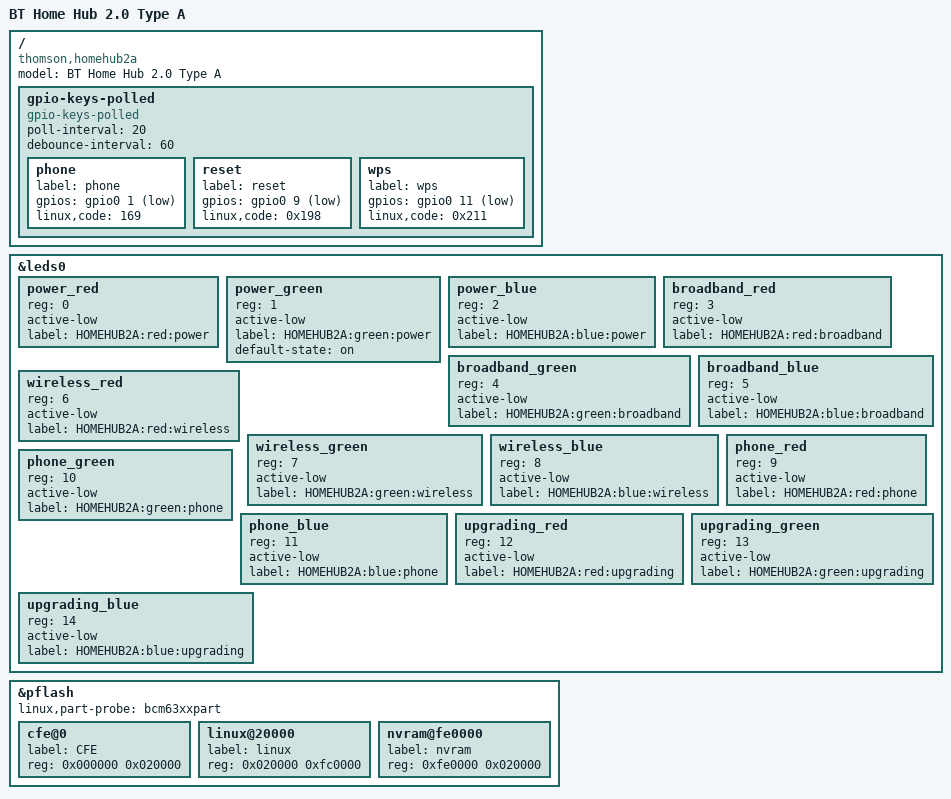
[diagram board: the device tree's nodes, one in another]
/dts-v1/;

/include/ "bcm6358.dtsi"

/ {
	model = "BT Home Hub 2.0 Type A";
	compatible = "thomson,homehub2a", "brcm,bcm6358";

	gpio-keys-polled {
		compatible = "gpio-keys-polled";
		#address-cells = <1>;
		#size-cells = <0>;
		poll-interval = <20>;
		debounce-interval = <60>;

		phone {
			label = "phone";
			gpios = <&gpio0 1 1>;
			linux,code = <169>;
		};
		reset {
			label = "reset";
			gpios = <&gpio0 9 1>;
			linux,code = <0x198>;
		};
		wps {
			label = "wps";
			gpios = <&gpio0 11 1>;
			linux,code = <0x211>;
		};
	};
};

&leds0 {
	status = "ok";

	power_red {
		reg = <0>;
		active-low;
		label = "HOMEHUB2A:red:power";
	};
	power_green {
		reg = <1>;
		active-low;
		label = "HOMEHUB2A:green:power";
		default-state = "on";
	};
	power_blue {
		reg = <2>;
		active-low;
		label = "HOMEHUB2A:blue:power";
	};
	broadband_red {
		reg = <3>;
		active-low;
		label = "HOMEHUB2A:red:broadband";
	};
	broadband_green {
		reg = <4>;
		active-low;
		label = "HOMEHUB2A:green:broadband";
	};
	broadband_blue {
		reg = <5>;
		active-low;
		label = "HOMEHUB2A:blue:broadband";
	};
	wireless_red {
		reg = <6>;
		active-low;
		label = "HOMEHUB2A:red:wireless";
	};
	wireless_green {
		reg = <7>;
		active-low;
		label = "HOMEHUB2A:green:wireless";
	};
	wireless_blue {
		reg = <8>;
		active-low;
		label = "HOMEHUB2A:blue:wireless";
	};
	phone_red {
		reg = <9>;
		active-low;
		label = "HOMEHUB2A:red:phone";
	};
	phone_green {
		reg = <10>;
		active-low;
		label = "HOMEHUB2A:green:phone";
	};
	phone_blue {
		reg = <11>;
		active-low;
		label = "HOMEHUB2A:blue:phone";
	};
	upgrading_red {
		reg = <12>;
		active-low;
		label = "HOMEHUB2A:red:upgrading";
	};
	upgrading_green {
		reg = <13>;
		active-low;
		label = "HOMEHUB2A:green:upgrading";
	};
	upgrading_blue {
		reg = <14>;
		active-low;
		label = "HOMEHUB2A:blue:upgrading";
	};
};

&pflash {
	status = "ok";

	linux,part-probe = "bcm63xxpart";

	cfe@0 {
		label = "CFE";
		reg = <0x000000 0x020000>;
	};

	linux@20000 {
		label = "linux";
		reg = <0x020000 0xfc0000>;
	};

	nvram@fe0000 {
		label = "nvram";
		reg = <0xfe0000 0x020000>;
	};
};
